# FM33FH0XX register map
File version: 1.0
CPU: SC000 r1p0, little endian, no MPU, no FPU, 3 interrupt priority bits
Registers are 32-bit, read-write, reset 0x0 unless marked. A register's access mark holds for its fields unless they carry their own. Offsets are from the block's base; [hi:lo] are bit positions.

## INTMUX — INTMUX module information
Base 0x40016000
0x00 CR0
  [31:0] MUX0SEL — MUX0SEL field description
0x04 CR1
  [31:0] MUX16SEL — MUX16SEL field description

## IWDT — IWDT module information
Base 0x40011400
0x00 SERV
  [31:0] SERV wo — SERV field description
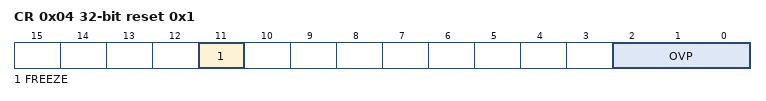
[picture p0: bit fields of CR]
0x04 CR reset 0x1
  [11] FREEZE — FREEZE field description
  [2:0] OVP — OVP field description
0x08 CNT
  [11:0] CNT ro — CNT field description
0x0C WIN
  [11:0] WIN — WIN field description
0x10 IER
  [0] IE — IE field description
0x14 ISR
  [0] WIN — WIN field description

## LPTIM16 — LPT16 module information
Base 0x40013400
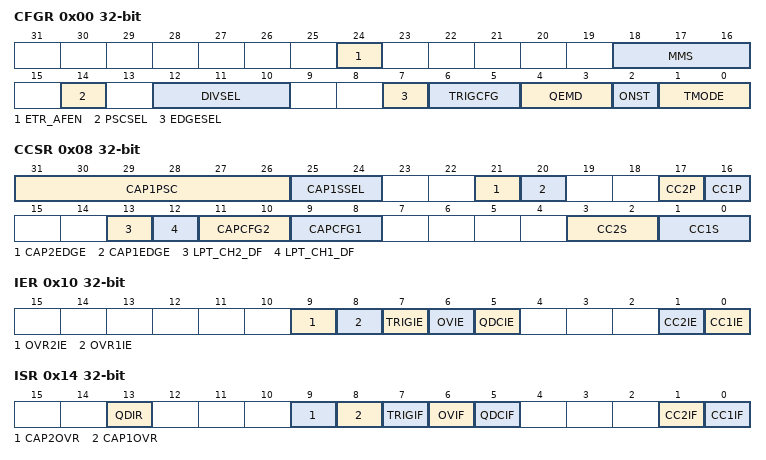
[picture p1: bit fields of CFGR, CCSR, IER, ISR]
0x00 CFGR
  [24] ETR_AFEN — ETR_AFEN field description
  [18:16] MMS — MMS field description
  [14] PSCSEL — PSCSEL field description
  [12:10] DIVSEL — DIVSEL field description
  [7] EDGESEL — EDGESEL field description
  [6:5] TRIGCFG — TRIGCFG field description
  [4:3] QEMD — QEMD field description
  [2] ONST — ONST field description
  [1:0] TMODE — TMODE field description
0x04 CNT
  [15:0] CNT ro — CNT field description
0x08 CCSR
  [31:26] CAP1PSC — CAP1PSC field description
  [25:24] CAP1SSEL — CAP1SSEL field description
  [21] CAP2EDGE ro — CAP2EDGE field description
  [20] CAP1EDGE ro — CAP1EDGE field description
  [17] CC2P — CC2P field description
  [16] CC1P — CC1P field description
  [13] LPT_CH2_DF — LPT_CH2_DF field description
  [12] LPT_CH1_DF — LPT_CH1_DF field description
  [11:10] CAPCFG2 — CAPCFG2 field description
  [9:8] CAPCFG1 — CAPCFG1 field description
  [3:2] CC2S — CC2S field description
  [1:0] CC1S — CC1S field description
0x0C ARR
  [15:0] ARR — ARR field description
0x10 IER
  [9] OVR2IE — OVR2IE field description
  [8] OVR1IE — OVR1IE field description
  [7] TRIGIE — TRIGIE field description
  [6] OVIE — OVIE field description
  [5] QDCIE — QDCIE field description
  [1] CC2IE — CC2IE field description
  [0] CC1IE — CC1IE field description
0x14 ISR
  [13] QDIR ro — QDIR field description
  [9] CAP2OVR — CAP2OVR field description
  [8] CAP1OVR — CAP1OVR field description
  [7] TRIGIF — TRIGIF field description
  [6] OVIF — OVIF field description
  [5] QDCIF — QDCIF field description
  [1] CC2IF — CC2IF field description
  [0] CC1IF — CC1IF field description
0x18 CR
  [0] EN — EN field description
0x20 CCR1
  [15:0] CCR1 — CCR1 field description
0x24 CCR2
  [15:0] CCR2 — CCR2 field description

## LPUART — LPUART module information
Base 0x40010400
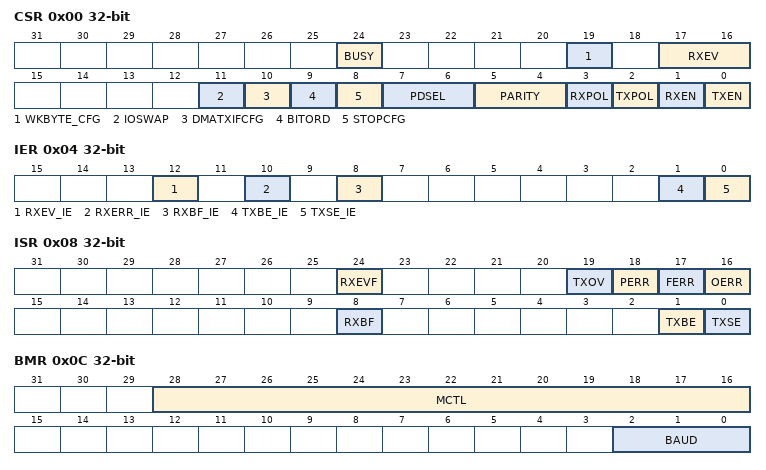
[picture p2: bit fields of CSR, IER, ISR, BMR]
0x00 CSR
  [24] BUSY ro — BUSY field description
  [19] WKBYTE_CFG — WKBYTE_CFG field description
  [17:16] RXEV — RXEV field description
  [11] IOSWAP — IOSWAP field description
  [10] DMATXIFCFG — DMATXIFCFG field description
  [9] BITORD — BITORD field description
  [8] STOPCFG — STOPCFG field description
  [7:6] PDSEL — PDSEL field description
  [5:4] PARITY — PARITY field description
  [3] RXPOL — RXPOL field description
  [2] TXPOL — TXPOL field description
  [1] RXEN — RXEN field description
  [0] TXEN — TXEN field description
0x04 IER
  [12] RXEV_IE — RXEV_IE field description
  [10] RXERR_IE — RXERR_IE field description
  [8] RXBF_IE — RXBF_IE field description
  [1] TXBE_IE — TXBE_IE field description
  [0] TXSE_IE — TXSE_IE field description
0x08 ISR
  [24] RXEVF — RXEVF field description
  [19] TXOV — TXOV field description
  [18] PERR — PERR field description
  [17] FERR — FERR field description
  [16] OERR — OERR field description
  [8] RXBF — RXBF field description
  [1] TXBE — TXBE field description
  [0] TXSE — TXSE field description
0x0C BMR
  [28:16] MCTL — MCTL field description
  [2:0] BAUD — BAUD field description
0x10 RXBUF
  [8:0] RXBUF ro — RXBUF field description
0x14 TXBUF
  [8:0] TXBUF wo — TXBUF field description
0x18 DMR
  [8:0] MATD — MATD field description
